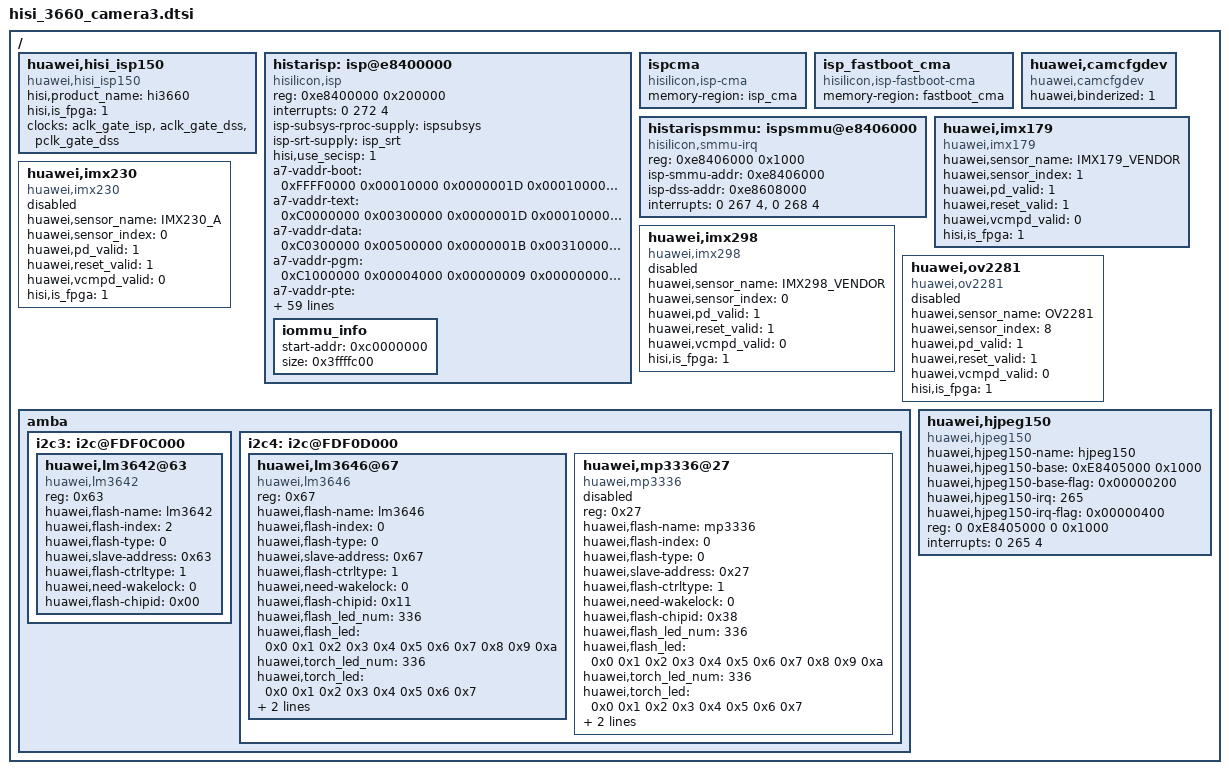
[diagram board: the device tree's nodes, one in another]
/*
 * Copyright (c) 2012-2013, The Linux Foundation. All rights reserved.
 *
 * This program is free software; you can redistribute it and/or modify
 * it under the terms of the GNU General Public License version 2 and
 * only version 2 as published by the Free Software Foundation.
 *
 * This program is distributed in the hope that it will be useful,
 * but WITHOUT ANY WARRANTY; without even the implied warranty of
 * MERCHANTABILITY or FITNESS FOR A PARTICULAR PURPOSE.  See the
 * GNU General Public License for more details.
 */
/ {
	huawei,hisi_isp150 {
		compatible = "huawei,hisi_isp150";
		hisi,product_name = "hi3660";
                hisi,is_fpga = <1>;

                clocks = <&aclk_gate_isp>, <&aclk_gate_dss>, <&pclk_gate_dss>;
                clock-names = "aclk_isp", "aclk_dss", "pclk_dss";

		status = "ok";
	};
	
    histarisp: isp@e8400000 {
        compatible = "hisilicon,isp";
        reg = <0xe8400000 0x200000>;
        interrupts = <0 272 4>;

        status = "ok";
        isp-subsys-rproc-supply = <&ispsubsys>;
        isp-srt-supply = <&isp_srt>;
        hisi,use_secisp = <1>;

        a7-vaddr-boot       = <0xFFFF0000 0x00010000 0x0000001D 0x00010000 0x00000001 0x0 0x0>;
        a7-vaddr-text       = <0xC0000000 0x00300000 0x0000001D 0x00010000 0x00000001 0x0 0x0>;
        a7-vaddr-data       = <0xC0300000 0x00500000 0x0000001B 0x00310000 0x00000001 0x0 0x0>;
        a7-vaddr-pgm        = <0xC1000000 0x00004000 0x00000009 0x00000000 0x00000001 0x0 0x0>;
        a7-vaddr-pte        = <0xC1100000 0x00200000 0x00000009 0x00810000 0x00000001 0x0 0x0>;
        a7-vaddr-rdr        = <0xC1800000 0x00040000 0x00000013 0x00000000 0x00000001 0x0 0x0>;
        a7-vaddr-shrd       = <0xC2000000 0x00001000 0x00000003 0x0000C000 0x00000001 0x00001000 0x00001000>;
        a7-vaddr-vq         = <0xC2020000 0x00040000 0x00000003 0x00000000 0x00000001 0x0 0x0>;
        a7-vaddr-vr0        = <0xC2060000 0x00004000 0x00000003 0x00000000 0x00000001 0x0 0x0>;
        a7-vaddr-vr1        = <0xC2064000 0x00004000 0x00000003 0x00000000 0x00000001 0x0 0x0>;
        a7-vaddr-heap       = <0xC4000000 0x01800000 0x0000001B 0x00000000 0x00000001 0x0 0x0>;
        a7-vaddr-a7dyna     = <0xD1000000 0x0F000000 0x00000013 0x00000000 0x00000000 0x00003000 0x0F000000>;

        a7-vaddr-regisp     = <0xE8400000 0x00200000 0x0000002B 0x00000000 0x00000001 0x0 0x0>;
        a7-vaddr-regipcs    = <0xE896A000 0x00001000 0x0000002B 0x00000000 0x00000001 0x0 0x0>;
        a7-vaddr-regipcns   = <0xE896B000 0x00001000 0x0000002B 0x00000000 0x00000001 0x0 0x0>;
        a7-vaddr-regpctrl   = <0xE8A09000 0x00001000 0x0000002B 0x00000000 0x00000001 0x0 0x0>;
        a7-vaddr-regsctrl   = <0xFFF0A000 0x00001000 0x0000002B 0x00000000 0x00000001 0x0 0x0>;
        a7-vaddr-regpcfg    = <0xFFF35000 0x00001000 0x0000002B 0x00000000 0x00000001 0x0 0x0>;
        a7-vaddr-reggic     = <0xE82B0000 0x00008000 0x0000002B 0x00000000 0x00000001 0x0 0x0>;
        a7-vaddr-regsysc    = <0xFFF09000 0x00001000 0x0000002B 0x00000000 0x00000001 0x0 0x0>;
        a7-vaddr-reguart    = <0xFFF32000 0x00001000 0x0000002B 0x00000000 0x00000001 0x0 0x0>;
        a7-vaddr-reggpio    = <0xE8A0B000 0x00016000 0x0000002B 0x00000000 0x00000001 0x0 0x0>;
        a7-vaddr-reggpio25  = <0xFFF0E000 0x00001000 0x0000002B 0x00000000 0x00000001 0x0 0x0>;
        a7-vaddr-regioc     = <0xE896C000 0x00001000 0x0000002B 0x00000000 0x00000001 0x0 0x0>;

		atf-shrd        = <0x00000000 0x00020000>;

        isp-remap-addr = <0x00000000>;
        isp-ipc-addr = <0xC2020000>;
        isp-iova-start = <0xC5900000>;
        isp-iova-size = <0xB700000>;
        isp-names = "isp_a7";
        firmware-names = "isp_fw.elf";
        bootware-names = "isp_bw.elf";
        mailbox-names = "isp_mailbox";
		isp_local_timer = <19200000>;
		ispa7-default-clk = <800000000>;
        clock-num = <2>;
		clocks = <&clk_gate_ispa7>, <&clk_gate_ispfunc>;
		clock-names = "clk_ispa7", "clk_ispfunc";
		clock-value = <800000000 480000000>;
		isp_nosec_flag = <0x0>;
        ispsmmu-init-byap = <0x1>;
        isp-mdc-flag    = <0x0>;
        isp-wdt-flag    = <0x0>;
        clk_flag = <0x0>;
        clk_dvfs = <0x0>;
        iommu_info{
            start-addr = <0xc0000000>;
            size = <0x3ffffc00>;
        };
    };

    ispcma {
        compatible = "hisilicon,isp-cma";
        memory-region = <&isp_cma>;
        status = "ok";
    };

    isp_fastboot_cma {
        compatible = "hisilicon,isp-fastboot-cma";
        memory-region = <&fastboot_cma>;
        status = "ok";
    };

    histarispsmmu: ispsmmu@e8406000 {
        compatible = "hisilicon,smmu-irq";
        reg = <0xe8406000 0x1000>;
            isp-smmu-addr = <0xe8406000>;
            isp-dss-addr = <0xe8608000>;
        interrupts = <0 267 4>,<0 268 4>;
        status = "ok";
    };

/* begin for hwcam arch  */

	huawei,camcfgdev {
			compatible = "huawei,camcfgdev";		
            huawei,binderized = <1>;
			status = "ok";
		};

	huawei,imx179 {
		compatible = "huawei,imx179";
		huawei,sensor_name = "IMX179_VENDOR";
		huawei,sensor_index = <1>; 
		huawei,pd_valid = <1>;
		huawei,reset_valid = <1>;
		huawei,vcmpd_valid = <0>;

        hisi,is_fpga = <1>;
		status = "ok";
	};

	huawei,imx230 {
		compatible = "huawei,imx230";
		huawei,sensor_name = "IMX230_A";
		huawei,sensor_index = <0>;
		huawei,pd_valid = <1>;
		huawei,reset_valid = <1>;
		huawei,vcmpd_valid = <0>;

        hisi,is_fpga = <1>;
		status = "disabled";
    };

    huawei,imx298 {
        compatible = "huawei,imx298";
        huawei,sensor_name = "IMX298_VENDOR";
        huawei,sensor_index = <0>;
        huawei,pd_valid = <1>;
        huawei,reset_valid = <1>;
        huawei,vcmpd_valid = <0>;

        hisi,is_fpga = <1>;
        status = "disabled";
    };

    huawei,ov2281 {
        compatible = "huawei,ov2281";
        huawei,sensor_name = "OV2281";
        huawei,sensor_index = <8>;
        huawei,pd_valid = <1>;
        huawei,reset_valid = <1>;
        huawei,vcmpd_valid = <0>;

        hisi,is_fpga = <1>;
        status = "disabled";
    };


    amba{

        i2c3: i2c@FDF0C000 {

            huawei,lm3642@63{
                compatible = "huawei,lm3642";
                reg = <0x63>;
                huawei,flash-name = "lm3642";
                huawei,flash-index = <2>;
                huawei,flash-type = <0>;
                huawei,slave-address = <0x63>;
                huawei,flash-ctrltype = <1>;
                huawei,need-wakelock = <0>;
                huawei,flash-chipid = <0x00>;
                status = "ok";
            };
        };

        i2c4: i2c@FDF0D000 {
            huawei,lm3646@67{
                compatible = "huawei,lm3646";
                reg = <0x67>;
                huawei,flash-name = "lm3646";
                huawei,flash-index = <0>;
                huawei,flash-type = <0>;
                huawei,slave-address = <0x67>;
                huawei,flash-ctrltype = <1>;
                huawei,need-wakelock = <0>;
                huawei,flash-chipid = <0x11>;
                huawei,flash_led_num = <336>;
                huawei,flash_led = <0x0 0x1 0x2 0x3 0x4 0x5 0x6 0x7 0x8 0x9 0xa>;
                huawei,torch_led_num = <336>;
                huawei,torch_led = <0x0 0x1 0x2 0x3 0x4 0x5 0x6 0x7>;
                huawei,led-type = <1>; /* 1, dual tempature; 0, dual white */
                huawei,flash-current = <0x7c 0x7f 0x0>;
                status = "ok";
            };
            huawei,mp3336@27{
                compatible = "huawei,mp3336";
                reg = <0x27>;
                huawei,flash-name = "mp3336";
                huawei,flash-index = <0>;
                huawei,flash-type = <0>;
                huawei,slave-address = <0x27>;
                huawei,flash-ctrltype = <1>;
                huawei,need-wakelock = <0>;
                huawei,flash-chipid = <0x38>;
                huawei,flash_led_num = <336>;
                huawei,flash_led = <0x0 0x1 0x2 0x3 0x4 0x5 0x6 0x7 0x8 0x9 0xa>;
                huawei,torch_led_num = <336>;
                huawei,torch_led = <0x0 0x1 0x2 0x3 0x4 0x5 0x6 0x7>;
                huawei,led-type = <1>; /* 1, dual tempature; 0, dual white */
                huawei,flash-current = <0xbe 0xbe 0x0>;
                status = "disabled";
            };
        };
    };
	huawei,hjpeg150 {
		compatible = "huawei,hjpeg150";
		huawei,hjpeg150-name = "hjpeg150";
		huawei,hjpeg150-base = <0xE8405000 0x1000>;
		huawei,hjpeg150-base-flag = <0x00000200>;
		huawei,hjpeg150-irq = <265>;
		huawei,hjpeg150-irq-flag = <0x00000400>;
		reg = <0 0xE8405000 0 0x1000>;
        interrupts = <0 265 4>;
		status = "ok";
	};
};
